VERSION ""

NS_ :

BS_:

BU_: SmartSensor SS_WaterTemperature4 SS_WaterTemperature3 SS_WaterTemperature2 SS_WaterTemperature1 SS_WaterPump2 SS_WaterPump1 SS_WaterFlow1 SS_SteeringAngle SS_RTDS SS_DFR SS_DFL SS_DRR SS_DRL VCU User Telemetry SS_BreakLight TorqueRequestPCB Distri Dashboard AclrGPS
VAL_TABLE_ Vt_sig_SetBreakLight 1 "TSAL ON" 0 "TSAL OFF" ;
VAL_TABLE_ Vt_sig_SetRTDS 1 "RTDS ON" 0 "RTDS OFF" ;
VAL_TABLE_ AliveSignal 1 "ONLINE" 0 "OFFLINE" ;

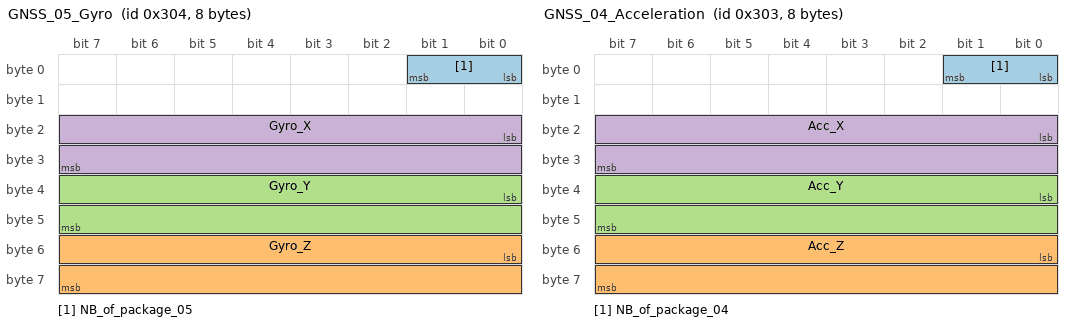
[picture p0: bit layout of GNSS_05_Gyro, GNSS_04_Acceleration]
BO_ 772 GNSS_05_Gyro: 8 AclrGPS
 SG_ NB_of_package_05 : 0|2@1+ (1,0) [0|3] ""  Telemetry
 SG_ Gyro_Z : 48|16@1- (0.00875,0) [-286.72|286.71125] ""  Telemetry
 SG_ Gyro_Y : 32|16@1- (0.00875,0) [-286.72|286.71125] ""  Telemetry
 SG_ Gyro_X : 16|16@1- (0.00875,0) [-286.72|286.71125] "rad/s"  Telemetry

BO_ 771 GNSS_04_Acceleration: 8 AclrGPS
 SG_ NB_of_package_04 : 0|2@1+ (1,0) [0|3] ""  Telemetry
 SG_ Acc_Z : 48|16@1- (0.061,0) [-1998.848|1998.787] "mG"  Telemetry
 SG_ Acc_Y : 32|16@1- (0.061,0) [-1998.848|1998.787] "mG"  Telemetry
 SG_ Acc_X : 16|16@1- (0.061,0) [-1998.848|1998.787] "mG"  Telemetry

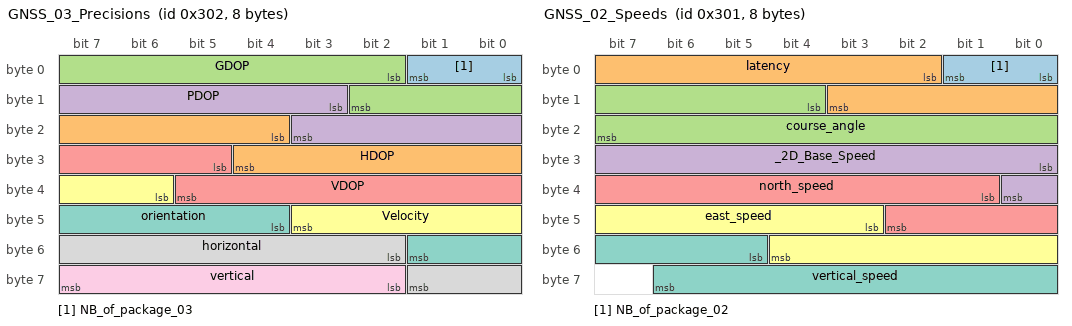
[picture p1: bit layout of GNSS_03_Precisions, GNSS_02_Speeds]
BO_ 770 GNSS_03_Precisions: 8 AclrGPS
 SG_ NB_of_package_03 : 0|2@1+ (1,0) [0|3] ""  Telemetry
 SG_ HDOP : 20|9@1+ (1,0) [0|0] ""  Telemetry
 SG_ GDOP : 2|9@1+ (1,0) [0|0] ""  Telemetry
 SG_ PDOP : 11|9@1+ (1,0) [0|0] ""  Telemetry
 SG_ VDOP : 29|9@1+ (1,0) [0|0] ""  Telemetry
 SG_ Velocity : 38|6@1+ (1,0) [0|0] ""  Telemetry
 SG_ orientation : 44|6@1+ (1,0) [0|0] ""  Telemetry
 SG_ horizontal : 50|8@1+ (1,0) [0|255] ""  Telemetry
 SG_ vertical : 58|6@1+ (1,0) [0|0] ""  Telemetry

BO_ 769 GNSS_02_Speeds: 8 AclrGPS
 SG_ NB_of_package_02 : 0|2@1+ (1,0) [0|3] ""  Telemetry
 SG_ latency : 2|10@1+ (1,0) [0|0] ""  Telemetry
 SG_ course_angle : 12|12@1+ (1,0) [0|0] ""  Telemetry
 SG_ _2D_Base_Speed : 24|9@1- (1,0) [0|0] ""  Telemetry
 SG_ north_speed : 33|10@1- (1,0) [-512|511] "m/sec"  Telemetry
 SG_ east_speed : 43|10@1- (1,0) [-512|511] "m/sec"  Telemetry
 SG_ vertical_speed : 53|10@1- (1,0) [-512|511] "m/sec"  Telemetry

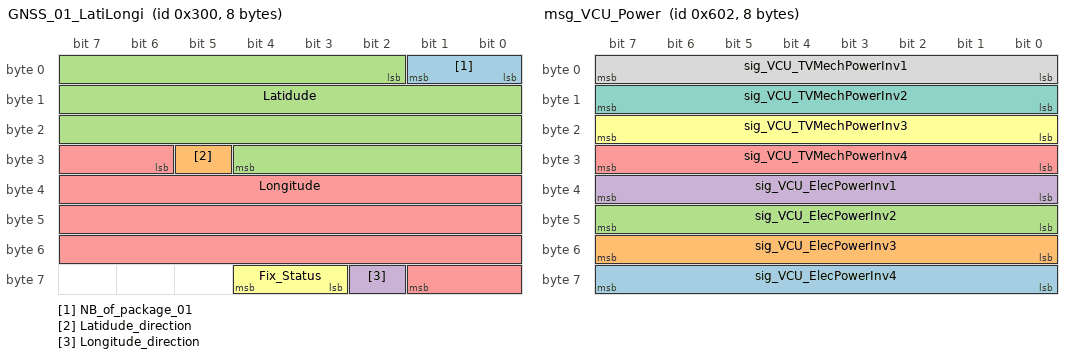
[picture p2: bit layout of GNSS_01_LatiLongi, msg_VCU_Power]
BO_ 768 GNSS_01_LatiLongi: 8 AclrGPS
 SG_ NB_of_package_01 : 0|2@1+ (1,0) [0|3] ""  Telemetry
 SG_ Latidude_direction : 29|1@1+ (1,0) [0|1] ""  Telemetry
 SG_ Latidude : 2|27@1+ (1,0) [0|268435455] ""  Telemetry
 SG_ Longitude_direction : 58|1@1+ (1,0) [0|1] ""  Telemetry
 SG_ Longitude : 30|28@1+ (1,0) [0|268435455] ""  Telemetry
 SG_ Fix_Status : 59|2@1+ (1,0) [0|3] ""  Telemetry

BO_ 1538 msg_VCU_Power: 8 VCU
 SG_ sig_VCU_ElecPowerInv4 : 56|8@1- (1,0) [-128|127] ""  Dashboard
 SG_ sig_VCU_ElecPowerInv3 : 48|8@1- (1,0) [-128|127] ""  Dashboard
 SG_ sig_VCU_ElecPowerInv2 : 40|8@1- (1,0) [-128|127] ""  Dashboard
 SG_ sig_VCU_ElecPowerInv1 : 32|8@1- (1,0) [-128|127] ""  Dashboard
 SG_ sig_VCU_TVMechPowerInv4 : 24|8@1- (1,0) [-128|127] ""  Dashboard
 SG_ sig_VCU_TVMechPowerInv3 : 16|8@1- (1,0) [-128|127] ""  Dashboard
 SG_ sig_VCU_TVMechPowerInv2 : 8|8@1- (1,0) [-128|127] ""  Dashboard
 SG_ sig_VCU_TVMechPowerInv1 : 0|8@1- (1,0) [-128|127] ""  Dashboard

BO_ 565 msg_UserToVCU_Commands: 8 User
 SG_ sig_User_VCUejectUSB : 0|1@1+ (1,0) [0|1] ""  VCU

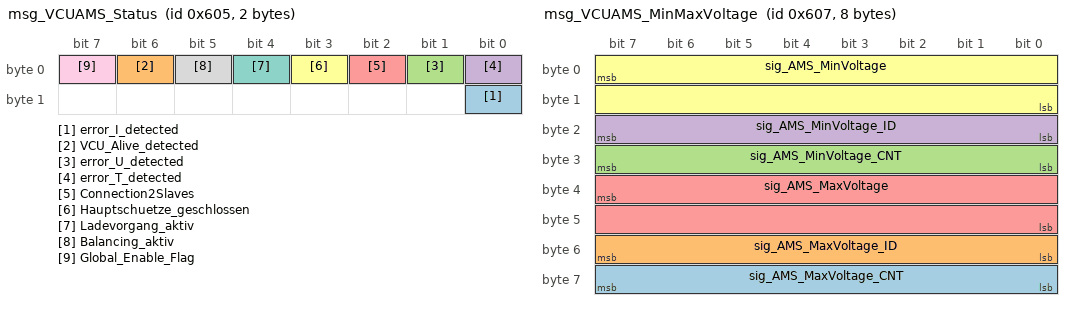
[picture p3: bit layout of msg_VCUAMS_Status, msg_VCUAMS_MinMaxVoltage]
BO_ 1541 msg_VCUAMS_Status: 2 VCU
 SG_ error_I_detected : 8|1@1+ (1,0) [0|1] ""  Dashboard
 SG_ VCU_Alive_detected : 6|1@1+ (1,0) [0|1] ""  Dashboard
 SG_ error_U_detected : 1|1@0+ (1,0) [0|0] ""  Dashboard
 SG_ error_T_detected : 0|1@0+ (1,0) [0|0] ""  Dashboard
 SG_ Connection2Slaves : 2|1@0+ (1,0) [0|0] ""  Dashboard
 SG_ Hauptschuetze_geschlossen : 3|1@0+ (1,0) [0|0] ""  Dashboard
 SG_ Ladevorgang_aktiv : 4|1@0+ (1,0) [0|0] ""  Dashboard
 SG_ Balancing_aktiv : 5|1@0+ (1,0) [0|0] ""  Dashboard
 SG_ Global_Enable_Flag : 7|1@0+ (1,0) [0|1] ""  Dashboard

BO_ 1542 msg_VCUAMS_Alive: 1 VCU
 SG_ AMS_Alive : 0|1@0+ (1,0) [0|0] ""  Dashboard

BO_ 1543 msg_VCUAMS_MinMaxVoltage: 8 VCU
 SG_ sig_AMS_MaxVoltage_CNT : 63|8@0+ (1,0) [0|255] ""  Dashboard
 SG_ sig_AMS_MaxVoltage_ID : 55|8@0+ (1,0) [0|255] ""  Dashboard
 SG_ sig_AMS_MinVoltage_CNT : 31|8@0+ (1,0) [0|255] ""  Dashboard
 SG_ sig_AMS_MinVoltage_ID : 23|8@0+ (1,0) [0|255] ""  Dashboard
 SG_ sig_AMS_MaxVoltage : 39|16@0+ (0.0001,0) [0|6.5535] "V"  Dashboard
 SG_ sig_AMS_MinVoltage : 7|16@0+ (0.0001,0) [0|6.5535] "V"  Dashboard

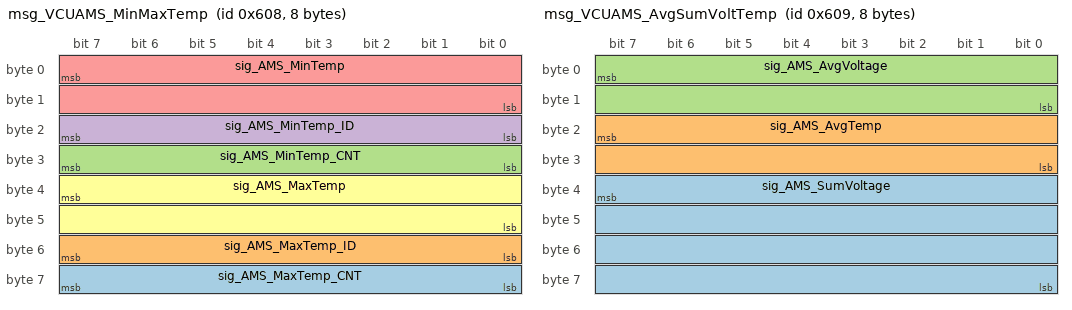
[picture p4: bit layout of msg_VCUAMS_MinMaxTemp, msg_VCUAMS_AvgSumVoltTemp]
BO_ 1544 msg_VCUAMS_MinMaxTemp: 8 VCU
 SG_ sig_AMS_MaxTemp_CNT : 63|8@0+ (1,0) [0|255] ""  VCU
 SG_ sig_AMS_MaxTemp_ID : 55|8@0+ (1,0) [0|255] ""  VCU
 SG_ sig_AMS_MinTemp_CNT : 31|8@0+ (1,0) [0|255] ""  VCU
 SG_ sig_AMS_MinTemp_ID : 23|8@0+ (1,0) [0|255] ""  VCU
 SG_ sig_AMS_MinTemp : 7|16@0+ (0.01,0) [0|65.535] ""  VCU
 SG_ sig_AMS_MaxTemp : 39|16@0+ (0.01,0) [0|65.535] ""  VCU

BO_ 1545 msg_VCUAMS_AvgSumVoltTemp: 8 VCU
 SG_ sig_AMS_SumVoltage : 39|32@0+ (0.0001,0) [0|429496.7295] ""  VCU
 SG_ sig_AMS_AvgTemp : 23|16@0+ (0.01,0) [0|65.535] ""  VCU
 SG_ sig_AMS_AvgVoltage : 7|16@0+ (0.0001,0) [0|6.5535] ""  VCU

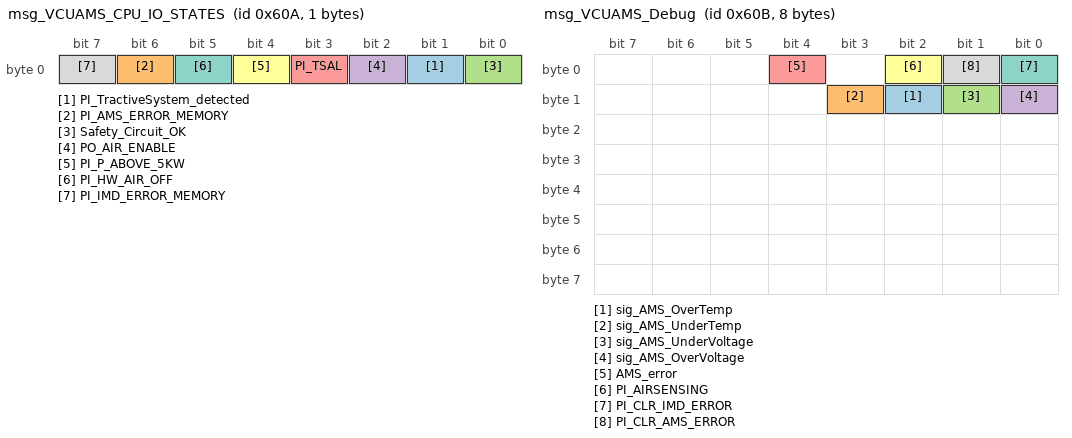
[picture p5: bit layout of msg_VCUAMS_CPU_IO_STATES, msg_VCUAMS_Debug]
BO_ 1546 msg_VCUAMS_CPU_IO_STATES: 1 VCU
 SG_ PI_TractiveSystem_detected : 1|1@1+ (1,0) [0|1] ""  Dashboard
 SG_ PI_AMS_ERROR_MEMORY : 6|1@1+ (1,0) [0|1] ""  Dashboard
 SG_ Safety_Circuit_OK : 0|1@0+ (1,0) [0|0] ""  Dashboard
 SG_ PO_AIR_ENABLE : 2|1@0+ (1,0) [0|0] ""  Dashboard
 SG_ PI_TSAL : 3|1@0+ (1,0) [0|0] ""  Dashboard
 SG_ PI_P_ABOVE_5KW : 4|1@0+ (1,0) [0|0] ""  Dashboard
 SG_ PI_HW_AIR_OFF : 5|1@0+ (1,0) [0|0] ""  Dashboard
 SG_ PI_IMD_ERROR_MEMORY : 7|1@0+ (1,0) [0|0] ""  Dashboard

BO_ 1547 msg_VCUAMS_Debug: 8 VCU
 SG_ sig_AMS_OverTemp : 10|1@0+ (1,0) [0|1] ""  VCU
 SG_ sig_AMS_UnderTemp : 11|1@0+ (1,0) [0|1] ""  VCU
 SG_ sig_AMS_UnderVoltage : 9|1@0+ (1,0) [0|1] ""  VCU
 SG_ sig_AMS_OverVoltage : 8|1@1+ (1,0) [0|1] ""  VCU
 SG_ AMS_error : 4|1@1+ (1,0) [0|0] ""  VCU
 SG_ PI_AIRSENSING : 2|1@1+ (1,0) [0|0] ""  VCU
 SG_ PI_CLR_IMD_ERROR : 0|1@1+ (1,0) [0|0] ""  VCU
 SG_ PI_CLR_AMS_ERROR : 1|1@1+ (1,0) [0|0] ""  VCU

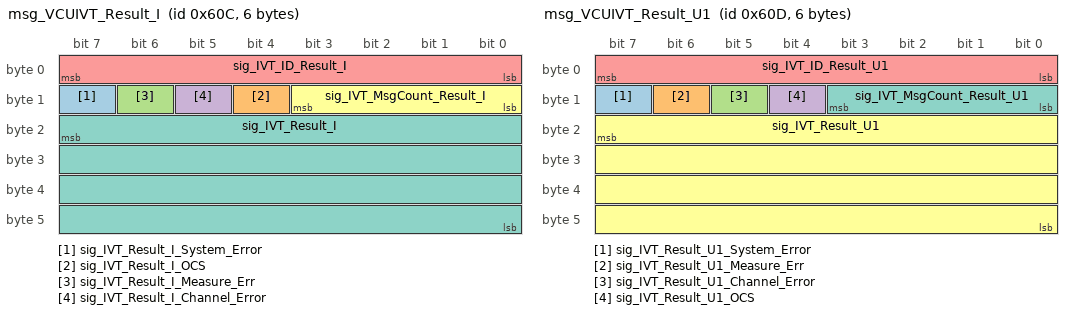
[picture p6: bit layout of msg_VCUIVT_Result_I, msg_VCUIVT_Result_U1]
BO_ 1548 msg_VCUIVT_Result_I: 6 VCU
 SG_ sig_IVT_Result_I_System_Error : 15|1@0+ (1,0) [0|0] ""  Dashboard
 SG_ sig_IVT_Result_I_OCS : 12|1@0+ (1,0) [0|0] ""  Dashboard
 SG_ sig_IVT_Result_I_Measure_Err : 14|1@0+ (1,0) [0|0] ""  Dashboard
 SG_ sig_IVT_Result_I_Channel_Error : 13|1@0+ (1,0) [0|0] ""  Dashboard
 SG_ sig_IVT_ID_Result_I : 7|8@0+ (1,0) [0|0] ""  Dashboard
 SG_ sig_IVT_MsgCount_Result_I : 11|4@0+ (1,0) [0|0] ""  Dashboard
 SG_ sig_IVT_Result_I : 23|32@0- (1,0) [0|0] "mA"  Dashboard

BO_ 1549 msg_VCUIVT_Result_U1: 6 VCU
 SG_ sig_IVT_Result_U1_System_Error : 15|1@0+ (1,0) [0|0] ""  Dashboard
 SG_ sig_IVT_Result_U1_Measure_Err : 14|1@0+ (1,0) [0|0] ""  Dashboard
 SG_ sig_IVT_Result_U1_Channel_Error : 13|1@0+ (1,0) [0|0] ""  Dashboard
 SG_ sig_IVT_Result_U1_OCS : 12|1@0+ (1,0) [0|0] ""  Dashboard
 SG_ sig_IVT_ID_Result_U1 : 7|8@0+ (1,0) [1|1] ""  Dashboard
 SG_ sig_IVT_Result_U1 : 23|32@0- (1,0) [0|0] "mV"  Dashboard
 SG_ sig_IVT_MsgCount_Result_U1 : 11|4@0+ (1,0) [0|0] ""  Dashboard

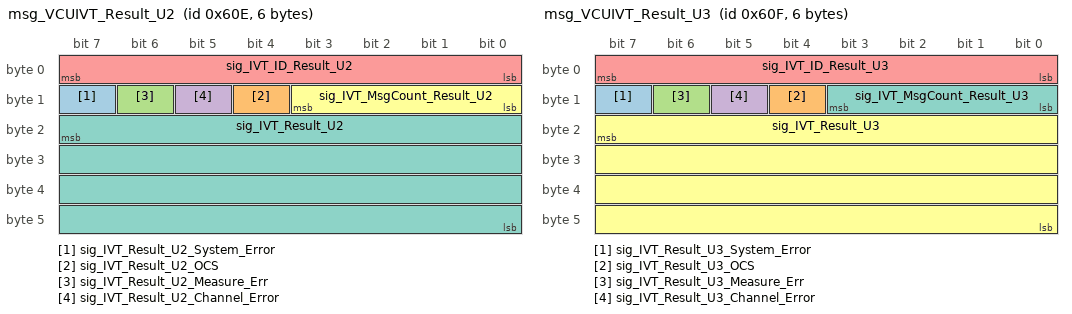
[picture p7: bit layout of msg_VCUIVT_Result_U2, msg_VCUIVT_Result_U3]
BO_ 1550 msg_VCUIVT_Result_U2: 6 VCU
 SG_ sig_IVT_Result_U2_System_Error : 15|1@0+ (1,0) [0|0] ""  Dashboard
 SG_ sig_IVT_Result_U2_OCS : 12|1@0+ (1,0) [0|0] ""  Dashboard
 SG_ sig_IVT_Result_U2_Measure_Err : 14|1@0+ (1,0) [0|0] ""  Dashboard
 SG_ sig_IVT_Result_U2_Channel_Error : 13|1@0+ (1,0) [0|0] ""  Dashboard
 SG_ sig_IVT_ID_Result_U2 : 7|8@0+ (1,0) [2|2] ""  Dashboard
 SG_ sig_IVT_MsgCount_Result_U2 : 11|4@0+ (1,0) [0|0] ""  Dashboard
 SG_ sig_IVT_Result_U2 : 23|32@0- (1,0) [0|0] "mV"  Dashboard

BO_ 1551 msg_VCUIVT_Result_U3: 6 VCU
 SG_ sig_IVT_Result_U3_System_Error : 15|1@0+ (1,0) [0|0] ""  Dashboard
 SG_ sig_IVT_Result_U3_OCS : 12|1@0+ (1,0) [0|0] ""  Dashboard
 SG_ sig_IVT_Result_U3_Measure_Err : 14|1@0+ (1,0) [0|0] ""  Dashboard
 SG_ sig_IVT_Result_U3_Channel_Error : 13|1@0+ (1,0) [0|0] ""  Dashboard
 SG_ sig_IVT_ID_Result_U3 : 7|8@0+ (1,0) [3|3] ""  Dashboard
 SG_ sig_IVT_Result_U3 : 23|32@0- (1,0) [0|0] "mV"  Dashboard
 SG_ sig_IVT_MsgCount_Result_U3 : 11|4@0+ (1,0) [0|0] ""  Dashboard

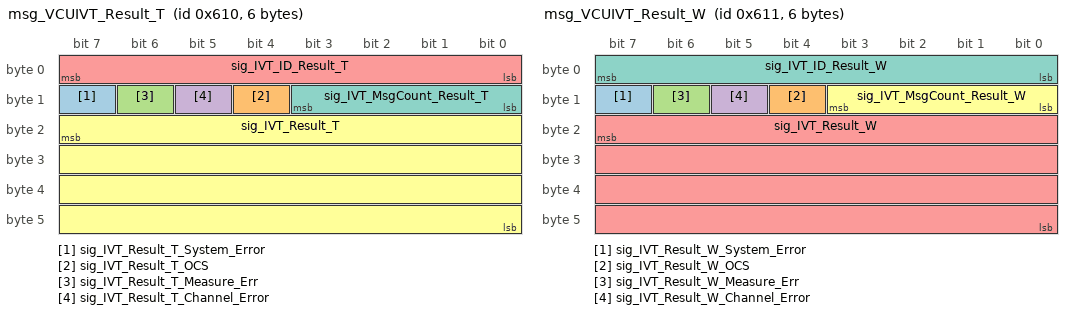
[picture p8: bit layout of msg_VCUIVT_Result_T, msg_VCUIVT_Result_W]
BO_ 1552 msg_VCUIVT_Result_T: 6 VCU
 SG_ sig_IVT_Result_T_System_Error : 15|1@0+ (1,0) [0|0] ""  Dashboard
 SG_ sig_IVT_Result_T_OCS : 12|1@0+ (1,0) [0|0] ""  Dashboard
 SG_ sig_IVT_Result_T_Measure_Err : 14|1@0+ (1,0) [0|0] ""  Dashboard
 SG_ sig_IVT_Result_T_Channel_Error : 13|1@0+ (1,0) [0|0] ""  Dashboard
 SG_ sig_IVT_ID_Result_T : 7|8@0+ (1,0) [4|4] ""  Dashboard
 SG_ sig_IVT_Result_T : 23|32@0- (1,0) [-32767|32768] "degC"  Dashboard
 SG_ sig_IVT_MsgCount_Result_T : 11|4@0+ (1,0) [0|0] ""  Dashboard

BO_ 1553 msg_VCUIVT_Result_W: 6 VCU
 SG_ sig_IVT_Result_W_System_Error : 15|1@0+ (1,0) [0|0] ""  Dashboard
 SG_ sig_IVT_Result_W_OCS : 12|1@0+ (1,0) [0|0] ""  Dashboard
 SG_ sig_IVT_Result_W_Measure_Err : 14|1@0+ (1,0) [0|0] ""  Dashboard
 SG_ sig_IVT_Result_W_Channel_Error : 13|1@0+ (1,0) [0|0] ""  Dashboard
 SG_ sig_IVT_Result_W : 23|32@0- (1,0) [0|0] "W"  Dashboard
 SG_ sig_IVT_MsgCount_Result_W : 11|4@0+ (1,0) [0|0] ""  Dashboard
 SG_ sig_IVT_ID_Result_W : 7|8@0+ (1,0) [5|5] ""  Dashboard

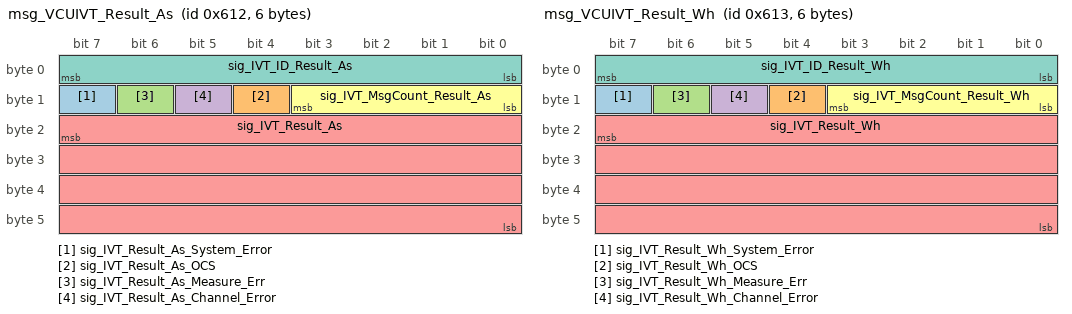
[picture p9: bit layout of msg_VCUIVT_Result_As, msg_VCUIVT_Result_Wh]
BO_ 1554 msg_VCUIVT_Result_As: 6 VCU
 SG_ sig_IVT_Result_As_System_Error : 15|1@0+ (1,0) [0|0] ""  Dashboard
 SG_ sig_IVT_Result_As_OCS : 12|1@0+ (1,0) [0|0] ""  Dashboard
 SG_ sig_IVT_Result_As_Measure_Err : 14|1@0+ (1,0) [0|0] ""  Dashboard
 SG_ sig_IVT_Result_As_Channel_Error : 13|1@0+ (1,0) [0|0] ""  Dashboard
 SG_ sig_IVT_Result_As : 23|32@0- (1,0) [0|0] "As"  Dashboard
 SG_ sig_IVT_MsgCount_Result_As : 11|4@0+ (1,0) [0|0] ""  Dashboard
 SG_ sig_IVT_ID_Result_As : 7|8@0+ (1,0) [6|6] ""  Dashboard

BO_ 1555 msg_VCUIVT_Result_Wh: 6 VCU
 SG_ sig_IVT_Result_Wh_System_Error : 15|1@0+ (1,0) [0|0] ""  Dashboard
 SG_ sig_IVT_Result_Wh_OCS : 12|1@0+ (1,0) [0|0] ""  Dashboard
 SG_ sig_IVT_Result_Wh_Measure_Err : 14|1@0+ (1,0) [0|0] ""  Dashboard
 SG_ sig_IVT_Result_Wh_Channel_Error : 13|1@0+ (1,0) [0|0] ""  Dashboard
 SG_ sig_IVT_Result_Wh : 23|32@0- (1,0) [0|0] "Wh"  Dashboard
 SG_ sig_IVT_MsgCount_Result_Wh : 11|4@0+ (1,0) [0|0] ""  Dashboard
 SG_ sig_IVT_ID_Result_Wh : 7|8@0+ (1,0) [7|7] ""  Dashboard

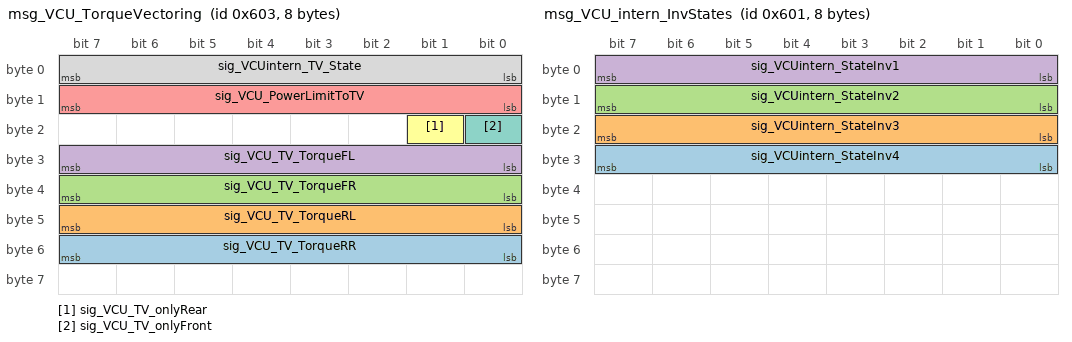
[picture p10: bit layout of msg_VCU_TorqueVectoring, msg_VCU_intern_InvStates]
BO_ 1539 msg_VCU_TorqueVectoring: 8 VCU
 SG_ sig_VCU_TV_TorqueRR : 48|8@1- (100,0) [-12800|12700] "" Vector__XXX
 SG_ sig_VCU_TV_TorqueRL : 40|8@1- (100,0) [-12800|12700] "" Vector__XXX
 SG_ sig_VCU_TV_TorqueFR : 32|8@1- (100,0) [-12800|12700] "" Vector__XXX
 SG_ sig_VCU_TV_TorqueFL : 24|8@1- (100,0) [-12800|12700] "" Vector__XXX
 SG_ sig_VCU_PowerLimitToTV : 8|8@1+ (1,0) [0|255] ""  Dashboard
 SG_ sig_VCU_TV_onlyRear : 17|1@1+ (1,0) [0|1] ""  Dashboard
 SG_ sig_VCU_TV_onlyFront : 16|1@1+ (1,0) [0|1] ""  Dashboard
 SG_ sig_VCUintern_TV_State : 0|8@1+ (1,0) [0|255] ""  Dashboard

BO_ 1537 msg_VCU_intern_InvStates: 8 VCU
 SG_ sig_VCUintern_StateInv4 : 24|8@1+ (1,0) [0|255] ""  Dashboard
 SG_ sig_VCUintern_StateInv3 : 16|8@1+ (1,0) [0|255] ""  Dashboard
 SG_ sig_VCUintern_StateInv2 : 8|8@1+ (1,0) [0|255] ""  Dashboard
 SG_ sig_VCUintern_StateInv1 : 0|8@1+ (1,0) [0|255] ""  Dashboard

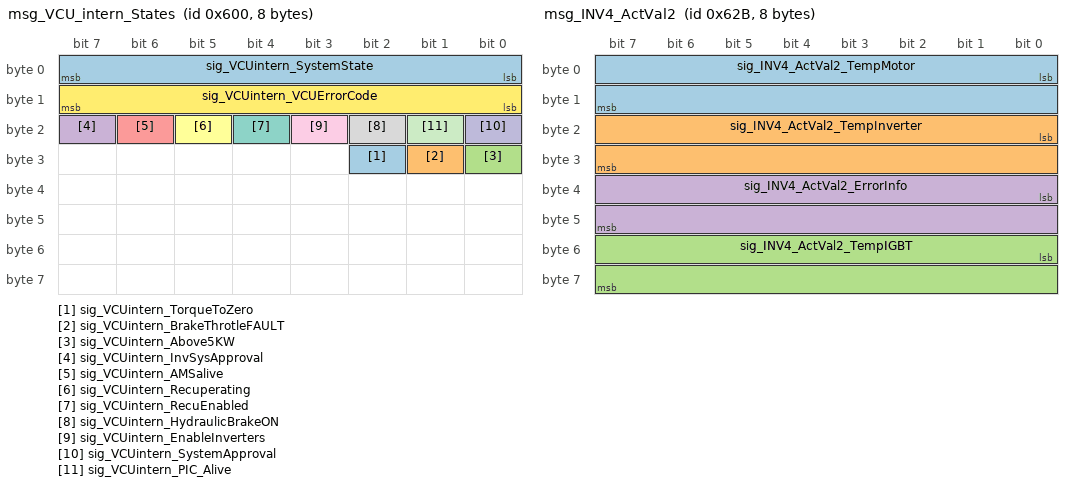
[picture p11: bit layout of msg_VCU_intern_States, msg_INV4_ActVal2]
BO_ 1536 msg_VCU_intern_States: 8 VCU
 SG_ sig_VCUintern_TorqueToZero : 26|1@1+ (1,0) [0|1] ""  Dashboard
 SG_ sig_VCUintern_BrakeThrotleFAULT : 25|1@1+ (1,0) [0|1] ""  Dashboard
 SG_ sig_VCUintern_Above5KW : 24|1@1+ (1,0) [0|0] ""  Dashboard
 SG_ sig_VCUintern_InvSysApproval : 23|1@1+ (1,0) [0|0] ""  Dashboard
 SG_ sig_VCUintern_AMSalive : 22|1@1+ (1,0) [0|0] ""  Dashboard
 SG_ sig_VCUintern_Recuperating : 21|1@1+ (1,0) [0|1] ""  Dashboard
 SG_ sig_VCUintern_RecuEnabled : 20|1@1+ (1,0) [0|1] ""  Dashboard
 SG_ sig_VCUintern_HydraulicBrakeON : 18|1@1+ (1,0) [0|1] ""  Dashboard
 SG_ sig_VCUintern_EnableInverters : 19|1@1+ (1,0) [0|1] ""  Dashboard
 SG_ sig_VCUintern_SystemApproval : 16|1@1+ (1,0) [0|1] ""  Dashboard
 SG_ sig_VCUintern_PIC_Alive : 17|1@1+ (1,0) [0|1] ""  Dashboard
 SG_ sig_VCUintern_VCUErrorCode : 8|8@1+ (1,0) [0|255] ""  Dashboard
 SG_ sig_VCUintern_SystemState : 0|8@1+ (1,0) [0|255] ""  Dashboard

BO_ 1579 msg_INV4_ActVal2: 8 VCU
 SG_ sig_INV4_ActVal2_TempMotor : 0|16@1- (0.1,0) [0|0] "°C"  Dashboard
 SG_ sig_INV4_ActVal2_TempInverter : 16|16@1- (0.1,0) [0|0] "°C"  Dashboard
 SG_ sig_INV4_ActVal2_TempIGBT : 48|16@1- (0.1,0) [0|0] "°C"  Dashboard
 SG_ sig_INV4_ActVal2_ErrorInfo : 32|16@1+ (1,0) [0|0] ""  Dashboard

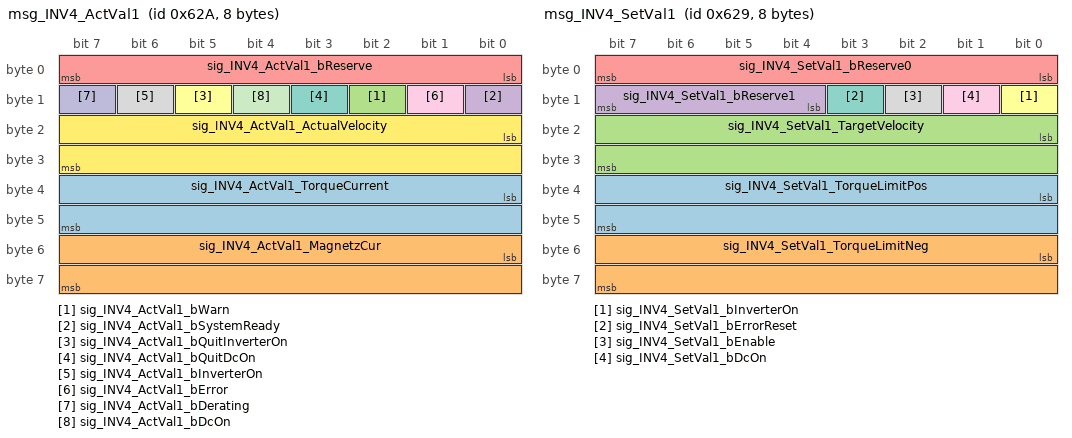
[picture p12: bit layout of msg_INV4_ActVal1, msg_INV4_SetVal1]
BO_ 1578 msg_INV4_ActVal1: 8 VCU
 SG_ sig_INV4_ActVal1_TorqueCurrent : 32|16@1- (1,0) [0|0] ""  Dashboard
 SG_ sig_INV4_ActVal1_MagnetzCur : 48|16@1- (1,0) [0|0] ""  Dashboard
 SG_ sig_INV4_ActVal1_bWarn : 10|1@1+ (1,0) [0|1] ""  Dashboard
 SG_ sig_INV4_ActVal1_bSystemReady : 8|1@1+ (1,0) [0|1] ""  Dashboard
 SG_ sig_INV4_ActVal1_bReserve : 0|8@1- (1,0) [0|0] ""  Dashboard
 SG_ sig_INV4_ActVal1_bQuitInverterOn : 13|1@1+ (1,0) [0|1] ""  Dashboard
 SG_ sig_INV4_ActVal1_bQuitDcOn : 11|1@1+ (1,0) [0|1] ""  Dashboard
 SG_ sig_INV4_ActVal1_bInverterOn : 14|1@1+ (1,0) [0|1] ""  Dashboard
 SG_ sig_INV4_ActVal1_bError : 9|1@1+ (1,0) [0|1] ""  Dashboard
 SG_ sig_INV4_ActVal1_bDerating : 15|1@1+ (1,0) [0|1] ""  Dashboard
 SG_ sig_INV4_ActVal1_bDcOn : 12|1@1+ (1,0) [0|0] ""  Dashboard
 SG_ sig_INV4_ActVal1_ActualVelocity : 16|16@1- (1,0) [0|0] "rpm"  Dashboard

BO_ 1577 msg_INV4_SetVal1: 8 VCU
 SG_ sig_INV4_SetVal1_TorqueLimitPos : 32|16@1- (0.0098,0) [0|0] "Nm"  Dashboard
 SG_ sig_INV4_SetVal1_TorqueLimitNeg : 48|16@1- (0.0098,0) [0|0] "Nm"  Dashboard
 SG_ sig_INV4_SetVal1_TargetVelocity : 16|16@1- (1,0) [0|0] "rpm"  Dashboard
 SG_ sig_INV4_SetVal1_bReserve1 : 12|4@1+ (1,0) [0|0] ""  Dashboard
 SG_ sig_INV4_SetVal1_bReserve0 : 0|8@1+ (1,0) [0|0] ""  Dashboard
 SG_ sig_INV4_SetVal1_bInverterOn : 8|1@1+ (1,0) [0|0] ""  Dashboard
 SG_ sig_INV4_SetVal1_bErrorReset : 11|1@1+ (1,0) [0|0] ""  Dashboard
 SG_ sig_INV4_SetVal1_bEnable : 10|1@1+ (1,0) [0|0] ""  Dashboard
 SG_ sig_INV4_SetVal1_bDcOn : 9|1@1+ (1,0) [0|0] ""  Dashboard

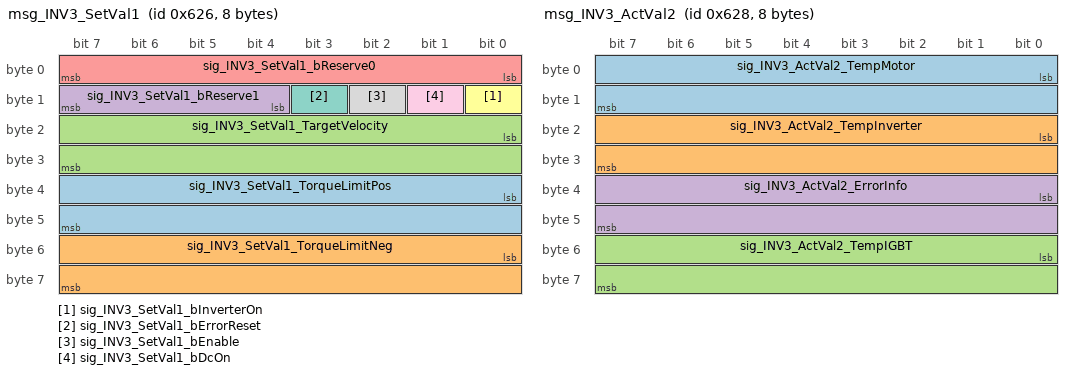
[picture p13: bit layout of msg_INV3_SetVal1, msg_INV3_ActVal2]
BO_ 1574 msg_INV3_SetVal1: 8 VCU
 SG_ sig_INV3_SetVal1_TorqueLimitPos : 32|16@1- (0.0098,0) [0|0] "Nm"  Dashboard
 SG_ sig_INV3_SetVal1_TorqueLimitNeg : 48|16@1- (0.0098,0) [0|0] "Nm"  Dashboard
 SG_ sig_INV3_SetVal1_TargetVelocity : 16|16@1- (1,0) [0|0] "rpm"  Dashboard
 SG_ sig_INV3_SetVal1_bReserve1 : 12|4@1+ (1,0) [0|0] ""  Dashboard
 SG_ sig_INV3_SetVal1_bReserve0 : 0|8@1+ (1,0) [0|0] ""  Dashboard
 SG_ sig_INV3_SetVal1_bInverterOn : 8|1@1+ (1,0) [0|0] ""  Dashboard
 SG_ sig_INV3_SetVal1_bErrorReset : 11|1@1+ (1,0) [0|0] ""  Dashboard
 SG_ sig_INV3_SetVal1_bEnable : 10|1@1+ (1,0) [0|0] ""  Dashboard
 SG_ sig_INV3_SetVal1_bDcOn : 9|1@1+ (1,0) [0|0] ""  Dashboard

BO_ 1576 msg_INV3_ActVal2: 8 VCU
 SG_ sig_INV3_ActVal2_TempMotor : 0|16@1- (0.1,0) [0|0] "°C"  Dashboard
 SG_ sig_INV3_ActVal2_TempInverter : 16|16@1- (0.1,0) [0|0] "°C"  Dashboard
 SG_ sig_INV3_ActVal2_TempIGBT : 48|16@1- (0.1,0) [0|0] "°C"  Dashboard
 SG_ sig_INV3_ActVal2_ErrorInfo : 32|16@1+ (1,0) [0|0] ""  Dashboard

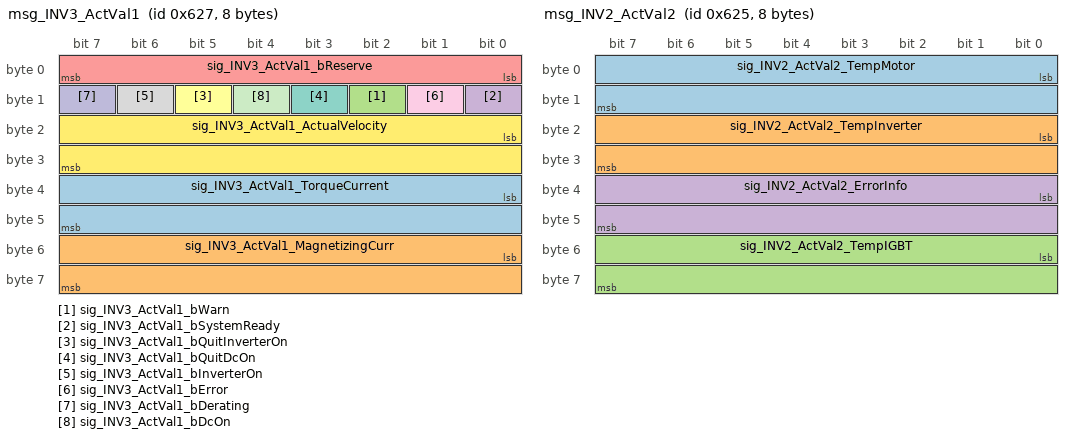
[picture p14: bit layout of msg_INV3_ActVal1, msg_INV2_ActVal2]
BO_ 1575 msg_INV3_ActVal1: 8 VCU
 SG_ sig_INV3_ActVal1_TorqueCurrent : 32|16@1- (1,0) [0|0] ""  Dashboard
 SG_ sig_INV3_ActVal1_MagnetizingCurr : 48|16@1- (1,0) [0|0] ""  Dashboard
 SG_ sig_INV3_ActVal1_bWarn : 10|1@1+ (1,0) [0|1] ""  Dashboard
 SG_ sig_INV3_ActVal1_bSystemReady : 8|1@1+ (1,0) [0|1] ""  Dashboard
 SG_ sig_INV3_ActVal1_bReserve : 0|8@1- (1,0) [0|0] ""  Dashboard
 SG_ sig_INV3_ActVal1_bQuitInverterOn : 13|1@1+ (1,0) [0|1] ""  Dashboard
 SG_ sig_INV3_ActVal1_bQuitDcOn : 11|1@1+ (1,0) [0|1] ""  Dashboard
 SG_ sig_INV3_ActVal1_bInverterOn : 14|1@1+ (1,0) [0|1] ""  Dashboard
 SG_ sig_INV3_ActVal1_bError : 9|1@1+ (1,0) [0|1] ""  Dashboard
 SG_ sig_INV3_ActVal1_bDerating : 15|1@1+ (1,0) [0|1] ""  Dashboard
 SG_ sig_INV3_ActVal1_bDcOn : 12|1@1+ (1,0) [0|0] ""  Dashboard
 SG_ sig_INV3_ActVal1_ActualVelocity : 16|16@1- (1,0) [0|0] "rpm"  Dashboard

BO_ 1573 msg_INV2_ActVal2: 8 VCU
 SG_ sig_INV2_ActVal2_TempMotor : 0|16@1- (0.1,0) [0|0] "°C"  Dashboard
 SG_ sig_INV2_ActVal2_TempInverter : 16|16@1- (0.1,0) [0|0] "°C"  Dashboard
 SG_ sig_INV2_ActVal2_TempIGBT : 48|16@1- (0.1,0) [0|0] "°C"  Dashboard
 SG_ sig_INV2_ActVal2_ErrorInfo : 32|16@1+ (1,0) [0|0] ""  Dashboard

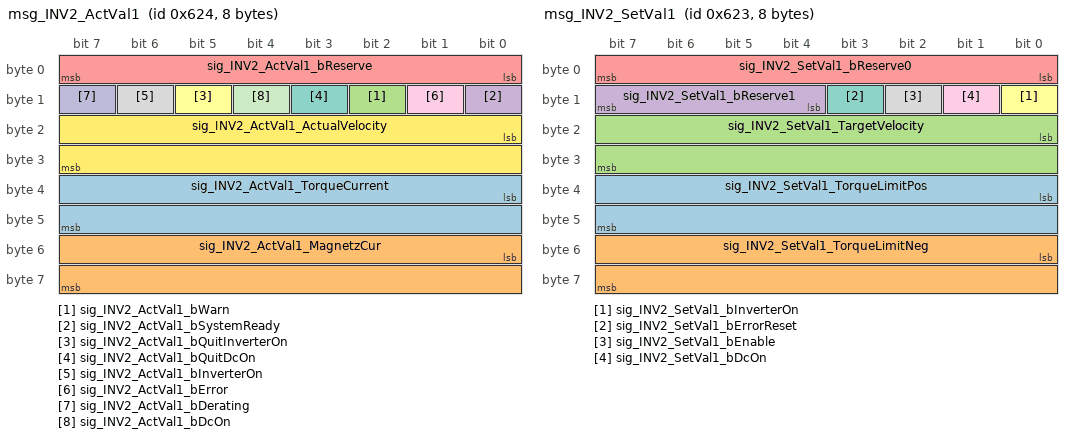
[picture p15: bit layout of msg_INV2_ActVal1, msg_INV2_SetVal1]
BO_ 1572 msg_INV2_ActVal1: 8 VCU
 SG_ sig_INV2_ActVal1_TorqueCurrent : 32|16@1- (1,0) [0|0] ""  Dashboard
 SG_ sig_INV2_ActVal1_MagnetzCur : 48|16@1- (1,0) [0|0] ""  Dashboard
 SG_ sig_INV2_ActVal1_bWarn : 10|1@1+ (1,0) [0|1] ""  Dashboard
 SG_ sig_INV2_ActVal1_bSystemReady : 8|1@1+ (1,0) [0|1] ""  Dashboard
 SG_ sig_INV2_ActVal1_bReserve : 0|8@1- (1,0) [0|0] ""  Dashboard
 SG_ sig_INV2_ActVal1_bQuitInverterOn : 13|1@1+ (1,0) [0|1] ""  Dashboard
 SG_ sig_INV2_ActVal1_bQuitDcOn : 11|1@1+ (1,0) [0|1] ""  Dashboard
 SG_ sig_INV2_ActVal1_bInverterOn : 14|1@1+ (1,0) [0|1] ""  Dashboard
 SG_ sig_INV2_ActVal1_bError : 9|1@1+ (1,0) [0|1] ""  Dashboard
 SG_ sig_INV2_ActVal1_bDerating : 15|1@1+ (1,0) [0|1] ""  Dashboard
 SG_ sig_INV2_ActVal1_bDcOn : 12|1@1+ (1,0) [0|0] ""  Dashboard
 SG_ sig_INV2_ActVal1_ActualVelocity : 16|16@1- (1,0) [0|0] "rpm"  Dashboard

BO_ 1571 msg_INV2_SetVal1: 8 VCU
 SG_ sig_INV2_SetVal1_TorqueLimitPos : 32|16@1- (0.0098,0) [0|0] "Nm"  Dashboard
 SG_ sig_INV2_SetVal1_TorqueLimitNeg : 48|16@1- (0.0098,0) [0|0] "Nm"  Dashboard
 SG_ sig_INV2_SetVal1_TargetVelocity : 16|16@1- (1,0) [0|0] "rpm"  Dashboard
 SG_ sig_INV2_SetVal1_bReserve1 : 12|4@1+ (1,0) [0|0] ""  Dashboard
 SG_ sig_INV2_SetVal1_bReserve0 : 0|8@1+ (1,0) [0|0] ""  Dashboard
 SG_ sig_INV2_SetVal1_bInverterOn : 8|1@1+ (1,0) [0|0] ""  Dashboard
 SG_ sig_INV2_SetVal1_bErrorReset : 11|1@1+ (1,0) [0|0] ""  Dashboard
 SG_ sig_INV2_SetVal1_bEnable : 10|1@1+ (1,0) [0|0] ""  Dashboard
 SG_ sig_INV2_SetVal1_bDcOn : 9|1@1+ (1,0) [0|0] ""  Dashboard

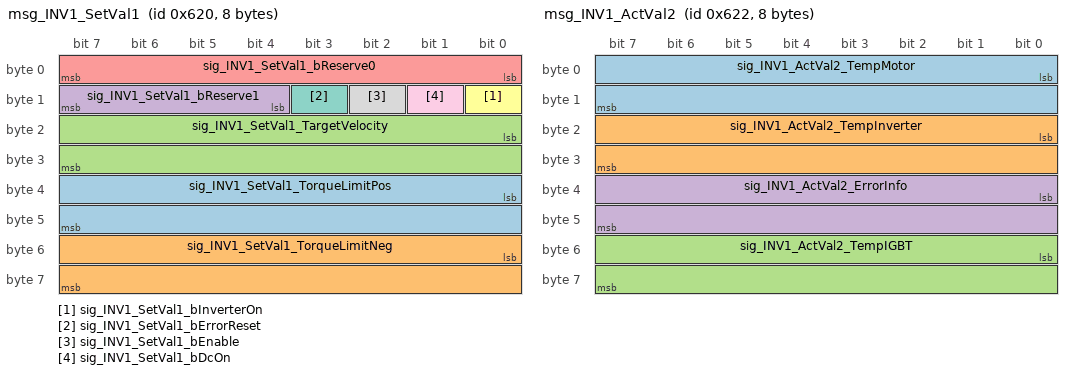
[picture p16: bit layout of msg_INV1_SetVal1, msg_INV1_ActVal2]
BO_ 1568 msg_INV1_SetVal1: 8 VCU
 SG_ sig_INV1_SetVal1_TorqueLimitPos : 32|16@1- (0.0098,0) [0|0] "Nm"  Dashboard
 SG_ sig_INV1_SetVal1_TorqueLimitNeg : 48|16@1- (0.0098,0) [0|0] "Nm"  Dashboard
 SG_ sig_INV1_SetVal1_TargetVelocity : 16|16@1- (1,0) [0|0] "rpm"  Dashboard
 SG_ sig_INV1_SetVal1_bReserve1 : 12|4@1+ (1,0) [0|0] ""  Dashboard
 SG_ sig_INV1_SetVal1_bReserve0 : 0|8@1+ (1,0) [0|0] ""  Dashboard
 SG_ sig_INV1_SetVal1_bInverterOn : 8|1@1+ (1,0) [0|0] ""  Dashboard
 SG_ sig_INV1_SetVal1_bErrorReset : 11|1@1+ (1,0) [0|0] ""  Dashboard
 SG_ sig_INV1_SetVal1_bEnable : 10|1@1+ (1,0) [0|0] ""  Dashboard
 SG_ sig_INV1_SetVal1_bDcOn : 9|1@1+ (1,0) [0|0] ""  Dashboard

BO_ 1570 msg_INV1_ActVal2: 8 VCU
 SG_ sig_INV1_ActVal2_TempMotor : 0|16@1- (0.1,0) [0|0] "°C"  Dashboard
 SG_ sig_INV1_ActVal2_TempInverter : 16|16@1- (0.1,0) [0|0] "°C"  Dashboard
 SG_ sig_INV1_ActVal2_TempIGBT : 48|16@1- (0.1,0) [0|0] "°C"  Dashboard
 SG_ sig_INV1_ActVal2_ErrorInfo : 32|16@1+ (1,0) [0|0] ""  Dashboard

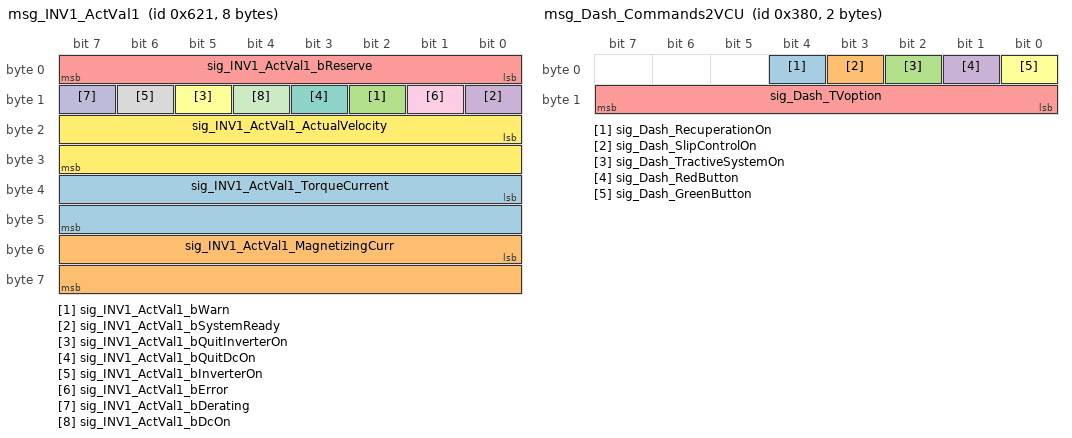
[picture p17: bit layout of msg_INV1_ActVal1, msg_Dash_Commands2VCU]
BO_ 1569 msg_INV1_ActVal1: 8 VCU
 SG_ sig_INV1_ActVal1_TorqueCurrent : 32|16@1- (1,0) [0|0] ""  Dashboard
 SG_ sig_INV1_ActVal1_MagnetizingCurr : 48|16@1- (1,0) [0|0] ""  Dashboard
 SG_ sig_INV1_ActVal1_bWarn : 10|1@1+ (1,0) [0|1] ""  Dashboard
 SG_ sig_INV1_ActVal1_bSystemReady : 8|1@1+ (1,0) [0|1] ""  Dashboard
 SG_ sig_INV1_ActVal1_bReserve : 0|8@1- (1,0) [0|0] ""  Dashboard
 SG_ sig_INV1_ActVal1_bQuitInverterOn : 13|1@1+ (1,0) [0|1] ""  Dashboard
 SG_ sig_INV1_ActVal1_bQuitDcOn : 11|1@1+ (1,0) [0|1] ""  Dashboard
 SG_ sig_INV1_ActVal1_bInverterOn : 14|1@1+ (1,0) [0|1] ""  Dashboard
 SG_ sig_INV1_ActVal1_bError : 9|1@1+ (1,0) [0|1] ""  Dashboard
 SG_ sig_INV1_ActVal1_bDerating : 15|1@1+ (1,0) [0|1] ""  Dashboard
 SG_ sig_INV1_ActVal1_bDcOn : 12|1@1+ (1,0) [0|0] ""  Dashboard
 SG_ sig_INV1_ActVal1_ActualVelocity : 16|16@1- (1,0) [0|0] "rpm"  Dashboard

BO_ 1061 msg_Calibrate_SS365: 1 VCU
 SG_ sig_Calibrate_SS365 : 0|1@1+ (1,0) [0|0] ""  SS_WaterPump2

BO_ 1060 msg_Calibrate_SS364: 1 VCU
 SG_ sig_Calibrate_SS364 : 0|1@1+ (1,0) [0|0] ""  SS_WaterPump1

BO_ 1059 msg_Calibrate_SS363: 1 VCU
 SG_ sig_Calibrate_SS363 : 0|1@1+ (1,0) [0|0] ""  SS_WaterTemperature4

BO_ 1058 msg_Calibrate_SS362: 1 VCU
 SG_ sig_Calibrate_SS362 : 0|1@1+ (1,0) [0|0] ""  SS_WaterTemperature3

BO_ 1057 msg_Calibrate_SS361: 1 VCU
 SG_ sig_Calibrate_SS361 : 0|1@1+ (1,0) [0|0] ""  SS_WaterTemperature2

BO_ 1056 msg_Calibrate_SS360: 1 VCU
 SG_ sig_Calibrate_SS360 : 0|1@1+ (1,0) [0|0] ""  SS_WaterTemperature1

BO_ 1055 msg_Calibrate_SS35F: 1 VCU
 SG_ sig_Calibrate_SS35F : 0|1@1+ (1,0) [0|0] ""  SS_WaterFlow1

BO_ 1054 msg_Calibrate_SS35E: 1 VCU
 SG_ sig_Calibrate_SS35E : 0|1@1+ (1,0) [0|0] ""  SmartSensor

BO_ 1053 msg_Calibrate_SS35D: 1 VCU
 SG_ sig_Calibrate_SS35D : 0|1@1+ (1,0) [0|0] ""  SmartSensor

BO_ 1052 msg_Calibrate_SS35C: 1 VCU
 SG_ sig_Calibrate_SS35C : 0|1@1+ (1,0) [0|0] ""  SmartSensor

BO_ 1051 msg_Calibrate_SS35B: 1 VCU
 SG_ sig_Calibrate_SS35B : 0|1@1+ (1,0) [0|0] ""  SmartSensor

BO_ 1050 msg_Calibrate_SS35A: 1 VCU
 SG_ sig_Calibrate_SS35A : 0|1@1+ (1,0) [0|0] ""  SmartSensor

BO_ 1049 msg_Calibrate_SS359: 1 VCU
 SG_ sig_Calibrate_SS359 : 0|1@1+ (1,0) [0|0] ""  SmartSensor

BO_ 1048 msg_Calibrate_SS358: 1 VCU
 SG_ sig_Calibrate_SS358 : 0|1@1+ (1,0) [0|0] ""  SmartSensor

BO_ 1047 msg_Calibrate_SS357: 1 VCU
 SG_ sig_Calibrate_SS357 : 0|1@1+ (1,0) [0|0] ""  SmartSensor

BO_ 1046 msg_Calibrate_SS356: 1 VCU
 SG_ sig_Calibrate_SS356 : 0|1@1+ (1,0) [0|0] ""  SmartSensor

BO_ 1045 msg_Calibrate_SS355: 1 VCU
 SG_ sig_Calibrate_SS355 : 0|1@1+ (1,0) [0|0] ""  SmartSensor

BO_ 1044 msg_Calibrate_SS354: 1 VCU
 SG_ sig_Calibrate_SS354 : 0|1@1+ (1,0) [0|0] ""  SS_SteeringAngle

BO_ 1043 msg_Calibrate_SS353: 1 VCU
 SG_ sig_Calibrate_SS353 : 0|1@1+ (1,0) [0|0] ""  SS_DRR

BO_ 1042 msg_Calibrate_SS352: 1 VCU
 SG_ sig_Calibrate_SS352 : 0|1@1+ (1,0) [0|0] ""  SS_DRL

BO_ 1041 msg_Calibrate_SS351: 1 VCU
 SG_ sig_Calibrate_SS351 : 0|1@1+ (1,0) [0|0] ""  SS_DFR

BO_ 1040 msg_Calibrate_SS350: 1 VCU
 SG_ sig_Calibrate_SS350 : 0|1@1+ (1,0) [0|0] ""  SS_DFL

BO_ 1024 msg_VCU_calibrateAllSS: 1 VCU
 SG_ sig_VCU_calibrateAllSS : 0|1@1+ (1,0) [0|0] ""  SS_WaterTemperature4,SS_WaterTemperature3,SS_WaterTemperature2,SS_WaterTemperature1,SS_WaterPump2,SS_WaterPump1,SS_WaterFlow1,SS_SteeringAngle,SS_RTDS,SS_DFR,SS_DFL,SS_DRR,SS_DRL,SS_BreakLight

BO_ 896 msg_Dash_Commands2VCU: 2 Dashboard
 SG_ sig_Dash_RecuperationOn : 4|1@1+ (1,0) [0|1] ""  VCU
 SG_ sig_Dash_SlipControlOn : 3|1@1+ (1,0) [0|0] ""  VCU
 SG_ sig_Dash_TractiveSystemOn : 2|1@1+ (1,0) [0|0] ""  VCU
 SG_ sig_Dash_RedButton : 1|1@1+ (1,0) [0|0] ""  VCU
 SG_ sig_Dash_TVoption : 8|8@1- (1,0) [0|0] ""  VCU
 SG_ sig_Dash_GreenButton : 0|1@1+ (1,0) [0|0] ""  VCU

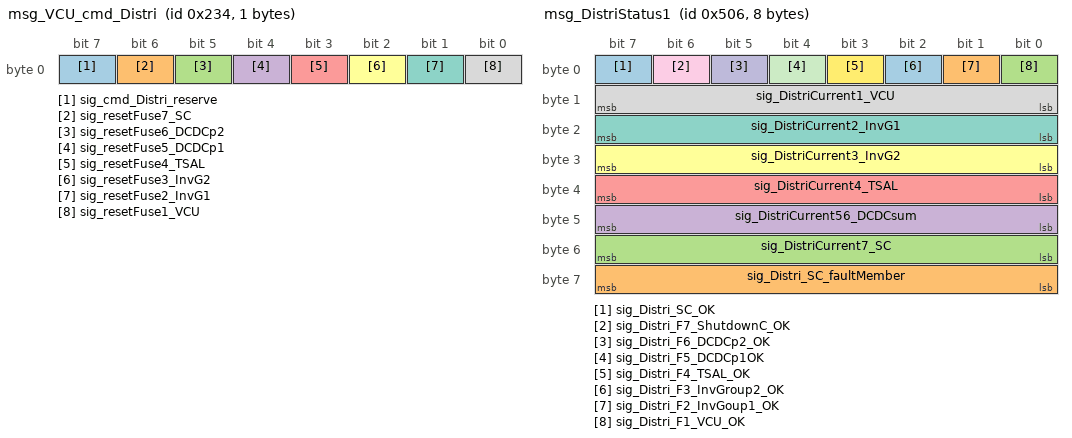
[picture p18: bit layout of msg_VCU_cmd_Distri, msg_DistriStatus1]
BO_ 564 msg_VCU_cmd_Distri: 1 VCU
 SG_ sig_cmd_Distri_reserve : 7|1@1+ (1,0) [0|0] ""  Distri
 SG_ sig_resetFuse7_SC : 6|1@1+ (1,0) [0|0] ""  Distri
 SG_ sig_resetFuse6_DCDCp2 : 5|1@1+ (1,0) [0|0] ""  Distri
 SG_ sig_resetFuse5_DCDCp1 : 4|1@1+ (1,0) [0|0] ""  Distri
 SG_ sig_resetFuse4_TSAL : 3|1@1+ (1,0) [0|0] ""  Distri
 SG_ sig_resetFuse3_InvG2 : 2|1@1+ (1,0) [0|0] ""  Distri
 SG_ sig_resetFuse2_InvG1 : 1|1@1+ (1,0) [0|0] ""  Distri
 SG_ sig_resetFuse1_VCU : 0|1@1+ (1,0) [0|0] ""  Distri

BO_ 1286 msg_DistriStatus1: 8 Distri
 SG_ sig_Distri_SC_OK : 7|1@1+ (1,0) [0|0] ""  VCU
 SG_ sig_Distri_SC_faultMember : 56|8@1+ (1,0) [0|255] ""  VCU
 SG_ sig_DistriCurrent7_SC : 48|8@1+ (1,0) [0|255] ""  VCU
 SG_ sig_DistriCurrent56_DCDCsum : 40|8@1+ (1,0) [0|255] ""  VCU
 SG_ sig_DistriCurrent4_TSAL : 32|8@1+ (1,0) [0|255] ""  VCU
 SG_ sig_DistriCurrent3_InvG2 : 24|8@1+ (1,0) [0|255] ""  VCU
 SG_ sig_DistriCurrent2_InvG1 : 16|8@1+ (1,0) [0|255] ""  VCU
 SG_ sig_DistriCurrent1_VCU : 8|8@1+ (1,0) [0|255] ""  VCU
 SG_ sig_Distri_F7_ShutdownC_OK : 6|1@1+ (1,0) [0|0] ""  VCU
 SG_ sig_Distri_F6_DCDCp2_OK : 5|1@1+ (1,0) [0|0] ""  VCU
 SG_ sig_Distri_F5_DCDCp1OK : 4|1@1+ (1,0) [0|0] ""  VCU
 SG_ sig_Distri_F4_TSAL_OK : 3|1@1+ (1,0) [0|0] ""  VCU
 SG_ sig_Distri_F3_InvGroup2_OK : 2|1@1+ (1,0) [0|0] ""  VCU
 SG_ sig_Distri_F2_InvGoup1_OK : 1|1@1+ (1,0) [0|0] ""  VCU
 SG_ sig_Distri_F1_VCU_OK : 0|1@1+ (1,0) [0|0] ""  VCU

BO_ 563 msg_VCU_cmd_PICoptions: 1 VCU
 SG_ sig_VCU_cmdPICverbose : 0|1@1+ (1,0) [0|0] ""  TorqueRequestPCB

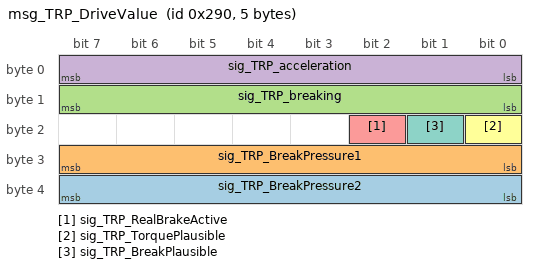
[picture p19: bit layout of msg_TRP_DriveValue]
BO_ 656 msg_TRP_DriveValue: 5 TorqueRequestPCB
 SG_ sig_TRP_BreakPressure2 : 32|8@1+ (1,0) [0|255] "bar"  VCU
 SG_ sig_TRP_BreakPressure1 : 24|8@1+ (1,0) [0|255] "bar"  VCU
 SG_ sig_TRP_breaking : 8|8@1+ (1,0) [0|255] ""  VCU
 SG_ sig_TRP_acceleration : 0|8@1+ (1,0) [0|255] ""  VCU
 SG_ sig_TRP_RealBrakeActive : 18|1@1+ (1,0) [0|0] ""  VCU
 SG_ sig_TRP_TorquePlausible : 16|1@1+ (1,0) [0|1] ""  VCU
 SG_ sig_TRP_BreakPlausible : 17|1@1+ (1,0) [0|0] ""  VCU

BO_ 863 msg_SS_WaterFlow1: 2 SS_WaterFlow1
 SG_ sig_WaterFlow1 : 0|16@1+ (1,0) [0|65535] ""  VCU

BO_ 561 msg_VCU_Alive: 1 VCU
 SG_ sig_VCU_Alive_Signal : 0|1@1+ (1,0) [0|0] ""  Dashboard

BO_ 800 msg_SS_CMD_BrakeLight: 1 VCU
 SG_ sig_cmd_SetBrakeLight : 0|1@1+ (1,0) [0|0] ""  SS_BreakLight

BO_ 801 msg_SS_CMD_RTDS: 1 VCU
 SG_ sig_SetRTDS : 0|1@1+ (1,0) [0|0] ""  SS_RTDS

BO_ 802 msg_SS_CMD_WaterPump1: 1 VCU
 SG_ sig_WaterPump1_ON : 0|1@1+ (1,0) [0|0] ""  SS_WaterPump1

BO_ 803 msg_SS_CMD_WaterPump2: 1 VCU
 SG_ sig_WaterPump2_ON : 0|1@1+ (1,0) [0|0] ""  SS_WaterPump2

BO_ 848 msg_SS_Deflection_FL: 2 SS_DFL
 SG_ sig_DeflectionFrontLeft : 0|16@1- (1,0) [-32768|32767] ""  VCU

BO_ 849 msg_SS_Deflection_FR: 2 SS_DFR
 SG_ sig_DeflectionFrontRight : 0|16@1- (1,0) [-32768|32767] ""  VCU

BO_ 850 msg_SS_Deflection_RL: 2 SS_DRL
 SG_ sig_DeflectionRearLeft : 0|16@1- (1,0) [-32768|32767] ""  VCU

BO_ 851 msg_SS_Deflection_RR: 2 SS_DRR
 SG_ sig_DeflectionRearRight : 0|16@1- (1,0) [-32768|32767] ""  VCU

BO_ 852 msg_SS_SteeringAngle: 2 SS_SteeringAngle
 SG_ sig_SteeringAngle : 0|16@1- (0.1,0) [-3276.8|3276.7] ""  VCU

BO_ 864 msg_SS_WaterTemp1: 2 SS_WaterTemperature1
 SG_ sig_TemperatureWater1 : 0|16@1+ (1,0) [0|65535] ""  VCU

BO_ 865 msg_SS_WaterTemp2: 2 SS_WaterTemperature2
 SG_ sig_TemperatureWater2 : 0|16@1+ (1,0) [0|65535] ""  VCU

BO_ 866 msg_SS_WaterTemp3: 2 SS_WaterTemperature3
 SG_ sig_TemperatureWater3 : 0|16@1+ (1,0) [0|65535] ""  VCU

BO_ 867 msg_SS_WaterTemp4: 2 SS_WaterTemperature4
 SG_ sig_TemperatureWater4 : 0|16@1+ (1,0) [0|65535] ""  VCU

BO_ 868 msg_SS_WaterPump1: 1 SS_WaterPump1
 SG_ sig_WaterPump1_State : 7|1@1+ (1,0) [0|0] ""  VCU

BO_ 869 msg_SS_WaterPump2: 1 SS_WaterPump2
 SG_ sig_WaterPump2_State : 7|1@1+ (1,0) [0|0] ""  VCU

BO_TX_BU_ 800 : User,VCU;
BO_TX_BU_ 801 : User,VCU;
BO_TX_BU_ 802 : User,VCU;
BO_TX_BU_ 803 : User,VCU;

CM_ BU_ SS_WaterTemperature4 "SmartSensor Water Temperature 4";
CM_ BU_ SS_WaterTemperature3 "SmartSensor Water Temperature 3";
CM_ BU_ SS_WaterTemperature2 "SmartSensor Water Temperature 2";
CM_ BU_ SS_WaterTemperature1 "SmartSensor Water Temperature 1";
CM_ BU_ SS_WaterPump2 "SmartSensor Water Pump 2";
CM_ BU_ SS_WaterPump1 "SmartSensor Water Pump 1";
CM_ BU_ SS_WaterFlow1 "SmartSensor Water Flow";
CM_ BU_ SS_SteeringAngle "SmartSensor steering angle";
CM_ BU_ SS_RTDS "SmartSensor ready to drive sound";
CM_ BU_ SS_DFR "SmartSensor Deflection Front Right";
CM_ BU_ SS_DFL "SmartSensor Deflection Front Left";
CM_ BU_ SS_DRR "Smart Sensor Deflection Rear Right";
CM_ BU_ SS_DRL "SmartSensor Deflection Rear Left";
CM_ BU_ User "extern developer eg. with CANoe";
CM_ BU_ SS_BreakLight "SmartSensor Brake Light";
CM_ BU_ TorqueRequestPCB "Pedalerie Platine (IC - integrated circuit)";
CM_ BU_ Distri "current distribution board. contains resatable e-fuses";
CM_ BU_ AclrGPS "ST Box, gyro and GPS sensors";
CM_ SG_ 1286 sig_Distri_F6_DCDCp2_OK "ein DCDC gesichert von 2 parallelen Stromkreisen -> 2 Fueses
";
CM_ SG_ 1286 sig_Distri_F5_DCDCp1OK "ein DCDC gesichert von 2 parallelen Stromkreisen -> 2 Fueses";
CM_ BO_ 656 "Message from TorqueRequestPCB";
VAL_ 561 sig_VCU_Alive_Signal 1 "ONLINE" 0 "OFFLINE" ;
VAL_ 800 sig_cmd_SetBrakeLight 1 "TSAL ON" 0 "TSAL OFF" ;
VAL_ 801 sig_SetRTDS 1 "RTDS ON" 0 "RTDS OFF" ;
